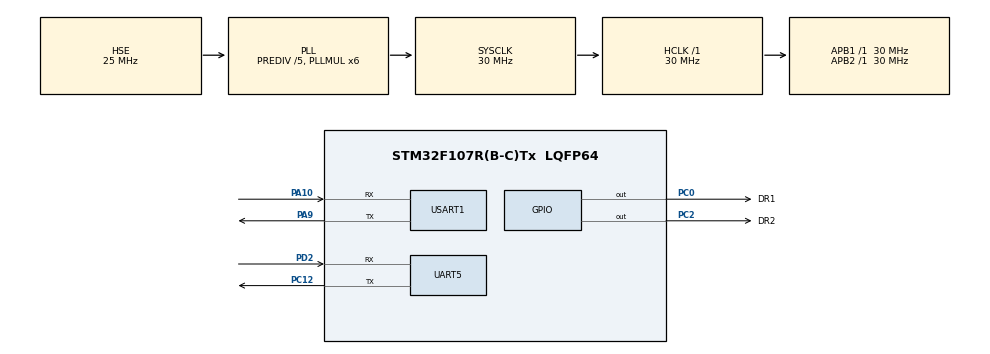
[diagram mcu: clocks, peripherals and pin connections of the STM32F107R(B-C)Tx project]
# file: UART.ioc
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Mcu.Family=STM32F1
Mcu.Name=STM32F107R(B-C)Tx
Mcu.Package=LQFP64
NVIC.PriorityGroup=NVIC_PRIORITYGROUP_4
PA10.Mode=Asynchronous
PA10.Signal=USART1_RX
PA13.Mode=Serial_Wire
PA13.Signal=SYS_JTMS-SWDIO
PA14.Mode=Serial_Wire
PA14.Signal=SYS_JTCK-SWCLK
PA9.Mode=Asynchronous
PA9.Signal=USART1_TX
PC0.GPIO_Label=DR1
PC0.GPIO_PuPd=GPIO_PULLUP
PC0.Signal=GPIO_Output
PC12.Mode=Asynchronous
PC12.Signal=UART5_TX
PC14-OSC32_IN.Mode=LSE-External-Oscillator
PC14-OSC32_IN.Signal=RCC_OSC32_IN
PC15-OSC32_OUT.Mode=LSE-External-Oscillator
PC15-OSC32_OUT.Signal=RCC_OSC32_OUT
PC2.GPIO_Label=DR2
PC2.GPIO_PuPd=GPIO_PULLUP
PC2.Signal=GPIO_Output
PD0-OSC_IN.Mode=HSE-External-Oscillator
PD0-OSC_IN.Signal=RCC_OSC_IN
PD1-OSC_OUT.Mode=HSE-External-Oscillator
PD1-OSC_OUT.Signal=RCC_OSC_OUT
PD2.Mode=Asynchronous
PD2.Signal=UART5_RX
ProjectManager.HeapSize=0x200
ProjectManager.StackSize=0x400
ProjectManager.TargetToolchain=MDK-ARM V5.27
RCC.AHBFreq_Value=30000000
RCC.APB1Freq_Value=30000000
RCC.APB1TimFreq_Value=30000000
RCC.APB2Freq_Value=30000000
RCC.APB2TimFreq_Value=30000000
RCC.HCLKFreq_Value=30000000
RCC.HSEDivPLL=RCC_HSE_PREDIV_DIV5
RCC.HSE_VALUE=25000000
RCC.PLLMUL=RCC_PLL_MUL6
RCC.PLLSourceVirtual=RCC_PLLSOURCE_HSE
RCC.SYSCLKFreq_VALUE=30000000
RCC.SYSCLKSource=RCC_SYSCLKSOURCE_PLLCLK
RCC.USBFreq_Value=20000000
UART5.VirtualMode=Asynchronous
USART1.VirtualMode=VM_ASYNC
board=custom

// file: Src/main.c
/* USER CODE BEGIN Header */
/**
  ******************************************************************************
  * @file           : main.c
  * @brief          : Main program body
  ******************************************************************************
  * @attention
  *
  * <h2><center>&copy; Copyright (c) 2020 STMicroelectronics.
  * All rights reserved.</center></h2>
  *
  * This software component is licensed by ST under BSD 3-Clause license,
  * the "License"; You may not use this file except in compliance with the
  * License. You may obtain a copy of the License at:
  *                        opensource.org/licenses/BSD-3-Clause
  *
  ******************************************************************************
  */
/* USER CODE END Header */

#include "main.h"

UART_HandleTypeDef huart5;
UART_HandleTypeDef huart1;

void SystemClock_Config(void);
static void MX_GPIO_Init(void);
static void MX_UART5_Init(void);
static void MX_USART1_UART_Init(void);

int main(void)
{

  /* MCU Configuration--------------------------------------------------------*/

  /* Reset of all peripherals, Initializes the Flash interface and the Systick. */
  HAL_Init();

  /* Configure the system clock */
  SystemClock_Config();

  /* Initialize all configured peripherals */
  MX_GPIO_Init();
  MX_UART5_Init();
  MX_USART1_UART_Init();
  /* USER CODE BEGIN 2 */
	HAL_GPIO_WritePin(GPIOC, DR2_Pin, GPIO_PIN_SET);
	HAL_GPIO_WritePin(GPIOC, DR1_Pin, GPIO_PIN_RESET);

  uint8_t rxbuf[10];

  /* USER CODE END 2 */

  /* Infinite loop */
  while (1)
  {

    /* USER CODE BEGIN 3 */
		if(HAL_UART_Receive(&huart5,rxbuf,1,100)==HAL_OK)
		{
		 HAL_UART_Transmit(&huart5,"hello5\r\n",8,100);
		 HAL_UART_Transmit(&huart1,"hello1\r\n",8,100);
		}
		HAL_Delay(10);
  }
  /* USER CODE END 3 */
}

void SystemClock_Config(void)
{
  RCC_OscInitTypeDef RCC_OscInitStruct = {0};
  RCC_ClkInitTypeDef RCC_ClkInitStruct = {0};

  /** Initializes the CPU, AHB and APB busses clocks
  */
  RCC_OscInitStruct.OscillatorType = RCC_OSCILLATORTYPE_HSE;
  RCC_OscInitStruct.HSEState = RCC_HSE_ON;
  RCC_OscInitStruct.HSEPredivValue = RCC_HSE_PREDIV_DIV5;
  RCC_OscInitStruct.HSIState = RCC_HSI_ON;
  RCC_OscInitStruct.Prediv1Source = RCC_PREDIV1_SOURCE_HSE;
  RCC_OscInitStruct.PLL.PLLState = RCC_PLL_ON;
  RCC_OscInitStruct.PLL.PLLSource = RCC_PLLSOURCE_HSE;
  RCC_OscInitStruct.PLL.PLLMUL = RCC_PLL_MUL6;
  RCC_OscInitStruct.PLL2.PLL2State = RCC_PLL_NONE;
  if (HAL_RCC_OscConfig(&RCC_OscInitStruct) != HAL_OK)
  {
    Error_Handler();
  }
  /** Initializes the CPU, AHB and APB busses clocks
  */
  RCC_ClkInitStruct.ClockType = RCC_CLOCKTYPE_HCLK|RCC_CLOCKTYPE_SYSCLK
                              |RCC_CLOCKTYPE_PCLK1|RCC_CLOCKTYPE_PCLK2;
  RCC_ClkInitStruct.SYSCLKSource = RCC_SYSCLKSOURCE_PLLCLK;
  RCC_ClkInitStruct.AHBCLKDivider = RCC_SYSCLK_DIV1;
  RCC_ClkInitStruct.APB1CLKDivider = RCC_HCLK_DIV1;
  RCC_ClkInitStruct.APB2CLKDivider = RCC_HCLK_DIV1;

  if (HAL_RCC_ClockConfig(&RCC_ClkInitStruct, FLASH_LATENCY_1) != HAL_OK)
  {
    Error_Handler();
  }
  /** Configure the Systick interrupt time
  */
  __HAL_RCC_PLLI2S_ENABLE();
}

static void MX_UART5_Init(void)
{

  huart5.Instance = UART5;
  huart5.Init.BaudRate = 115200;
  huart5.Init.WordLength = UART_WORDLENGTH_8B;
  huart5.Init.StopBits = UART_STOPBITS_1;
  huart5.Init.Parity = UART_PARITY_NONE;
  huart5.Init.Mode = UART_MODE_TX_RX;
  huart5.Init.HwFlowCtl = UART_HWCONTROL_NONE;
  huart5.Init.OverSampling = UART_OVERSAMPLING_16;
  if (HAL_UART_Init(&huart5) != HAL_OK)
  {
    Error_Handler();
  }

}

static void MX_USART1_UART_Init(void)
{

  huart1.Instance = USART1;
  huart1.Init.BaudRate = 115200;
  huart1.Init.WordLength = UART_WORDLENGTH_8B;
  huart1.Init.StopBits = UART_STOPBITS_1;
  huart1.Init.Parity = UART_PARITY_NONE;
  huart1.Init.Mode = UART_MODE_TX_RX;
  huart1.Init.HwFlowCtl = UART_HWCONTROL_NONE;
  huart1.Init.OverSampling = UART_OVERSAMPLING_16;
  if (HAL_UART_Init(&huart1) != HAL_OK)
  {
    Error_Handler();
  }

}

static void MX_GPIO_Init(void)
{
  GPIO_InitTypeDef GPIO_InitStruct = {0};

  /* GPIO Ports Clock Enable */
  __HAL_RCC_GPIOC_CLK_ENABLE();
  __HAL_RCC_GPIOD_CLK_ENABLE();
  __HAL_RCC_GPIOA_CLK_ENABLE();

  /*Configure GPIO pin Output Level */
  HAL_GPIO_WritePin(GPIOC, DR1_Pin|DR2_Pin, GPIO_PIN_RESET);

  /*Configure GPIO pins : DR1_Pin DR2_Pin */
  GPIO_InitStruct.Pin = DR1_Pin|DR2_Pin;
  GPIO_InitStruct.Mode = GPIO_MODE_OUTPUT_PP;
  GPIO_InitStruct.Pull = GPIO_PULLUP;
  GPIO_InitStruct.Speed = GPIO_SPEED_FREQ_LOW;
  HAL_GPIO_Init(GPIOC, &GPIO_InitStruct);

}

void Error_Handler(void)
{
}

/************************ (C) COPYRIGHT STMicroelectronics *****END OF FILE****/
